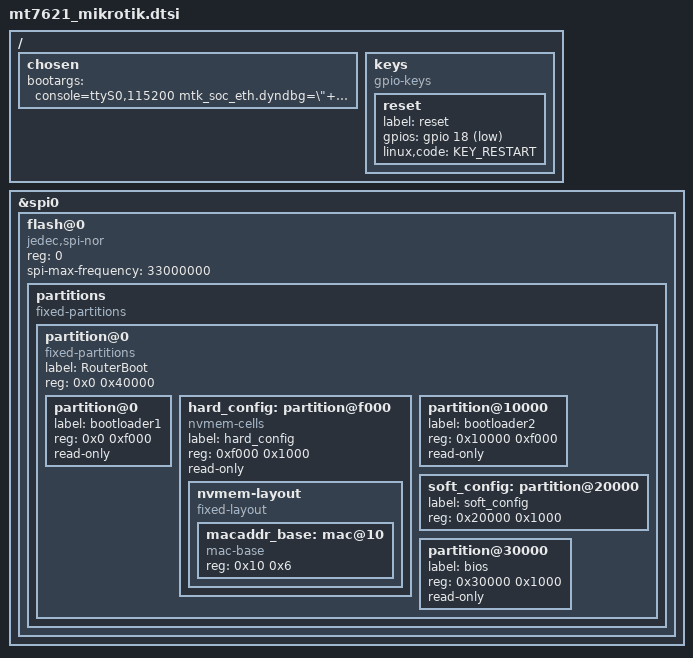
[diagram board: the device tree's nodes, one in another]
// SPDX-License-Identifier: GPL-2.0-or-later OR MIT

#include "mt7621.dtsi"

#include <dt-bindings/input/input.h>
#include <dt-bindings/gpio/gpio.h>

/ {
	chosen {
		bootargs = "console=ttyS0,115200 mtk_soc_eth.dyndbg=\"+p\" sfp.dyndbg=\"+p\" at803x.dyndbg=\"+p\" dyndbg=\"file drivers/platform/mikrotik/* +p\"";
	};

	keys: keys {
		compatible = "gpio-keys";

		reset {
			label = "reset";
			gpios = <&gpio 18 GPIO_ACTIVE_LOW>;
			linux,code = <KEY_RESTART>;
		};
	};
};

&spi0 {
	status = "okay";

	flash@0 {
		compatible = "jedec,spi-nor";
		reg = <0>;
		spi-max-frequency = <33000000>;

		partitions: partitions {
			compatible = "fixed-partitions";
			#address-cells = <1>;
			#size-cells = <1>;

			partition@0 {
				label = "RouterBoot";
				reg = <0x0 0x40000>;
				compatible = "fixed-partitions";
				#address-cells = <1>;
				#size-cells = <1>;

				partition@0 {
					label = "bootloader1";
					reg = <0x0 0xf000>;
					read-only;
				};

				hard_config: partition@f000 {
					label = "hard_config";
					reg = <0xf000 0x1000>;
					read-only;
					compatible = "nvmem-cells";

					nvmem-layout {
						compatible = "fixed-layout";
						#address-cells = <1>;
						#size-cells = <1>;

						macaddr_base: mac@10 {
							compatible = "mac-base";
							reg = <0x10 0x6>;
							#nvmem-cell-cells = <1>;
						};

					};
				};

				partition@10000 {
					label = "bootloader2";
					reg = <0x10000 0xf000>;
					read-only;
				};

				soft_config: partition@20000 {
					label = "soft_config";
					reg = <0x20000 0x1000>;
				};

				partition@30000 {
					label = "bios";
					reg = <0x30000 0x1000>;
					read-only;
				};
			};
		};
	};
};
